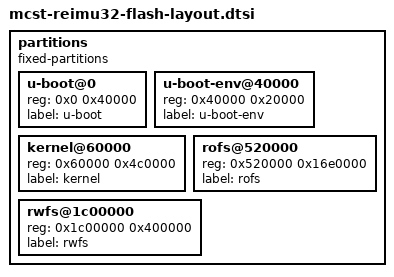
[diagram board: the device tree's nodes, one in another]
// SPDX-License-Identifier: GPL-2.0+

partitions {
	compatible = "fixed-partitions";
	#address-cells = <1>;
	#size-cells = <1>;

	u-boot@0 {
		reg = <0x0 0x40000>;
		label = "u-boot";
	};

	u-boot-env@40000 {
		reg = <0x40000 0x20000>;
		label = "u-boot-env";
	};

	kernel@60000 {
		reg = <0x60000 0x4c0000>;
		label = "kernel";
	};

	rofs@520000 {
		reg = <0x520000 0x16e0000>;
		label = "rofs";
	};

	rwfs@1c00000 {
		reg = <0x1c00000 0x400000>;
		label = "rwfs";
	};
};
